AUTOSAR XML (schema 4-3-0)
package /Dimmer
  application-sw-component-type:
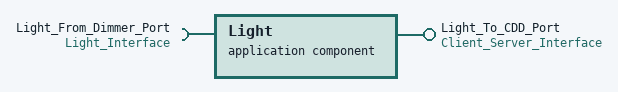
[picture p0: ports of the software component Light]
    application sw component type Light
      require port Light_From_Dimmer_Port: nonqueued-receiver-com-spec=Struct_Data_Element, required-interface=Light_Interface
      provide port Light_To_CDD_Port: server-com-spec=Op1, provided-interface=Client_Server_Interface
      behavior Light_InternalBehavior
    swc implementation Light_Implementation: behavior=Light_InternalBehavior
